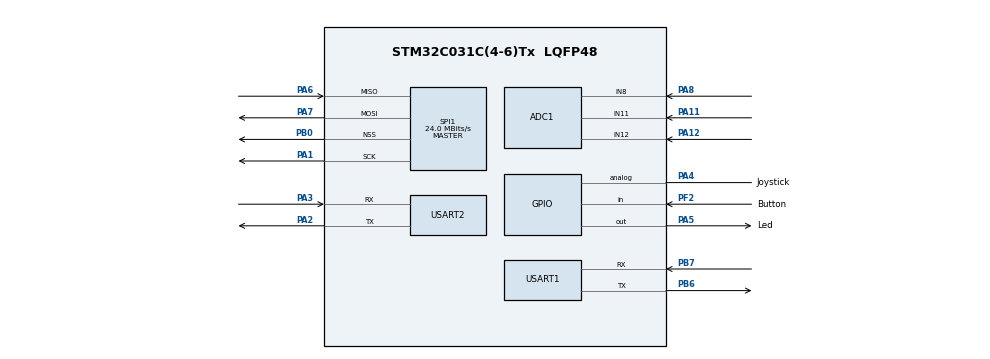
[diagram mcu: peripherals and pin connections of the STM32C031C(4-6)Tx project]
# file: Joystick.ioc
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ADC1.Channel-3\#ChannelRegularConversion=ADC_CHANNEL_11
ADC1.NbrOfConversionFlag=1
ADC1.Rank-3\#ChannelRegularConversion=1
ADC1.SamplingTime-3\#ChannelRegularConversion=ADC_SAMPLINGTIME_COMMON_1
ADC1.SelectedChannel=ADC_CHANNEL_8|ADC_CHANNEL_11|ADC_CHANNEL_12
ADC1.master=1
Mcu.Family=STM32C0
Mcu.Name=STM32C031C(4-6)Tx
Mcu.Package=LQFP48
NVIC.USART2_IRQn=true\:0\:0\:false\:false\:true\:true\:true\:true
PA1.Mode=Full_Duplex_Master
PA1.Signal=SPI1_SCK
PA11\ [PA9].Mode=IN11
PA11\ [PA9].Signal=ADC1_IN11
PA12\ [PA10].Mode=IN12
PA12\ [PA10].Signal=ADC1_IN12
PA13.Mode=Serial_Wire
PA13.Signal=DEBUG_SWDIO
PA14-BOOT0.Mode=Serial_Wire
PA14-BOOT0.Signal=DEBUG_SWCLK
PA2.Mode=Asynchronous
PA2.Signal=USART2_TX
PA3.Mode=Asynchronous
PA3.Signal=USART2_RX
PA4.GPIO_Label=Joystick
PA4.GPIO_Mode=GPIO_MODE_ANALOG
PA4.Signal=GPIO_Analog
PA5.GPIO_Label=Led
PA5.GPIO_ModeDefaultOutputPP=GPIO_MODE_OUTPUT_PP
PA5.GPIO_PuPd=GPIO_NOPULL
PA5.GPIO_Speed=GPIO_SPEED_FREQ_VERY_HIGH
PA5.PinState=GPIO_PIN_SET
PA5.Signal=GPIO_Output
PA6.Mode=Full_Duplex_Master
PA6.Signal=SPI1_MISO
PA7.Mode=Full_Duplex_Master
PA7.Signal=SPI1_MOSI
PA8.Mode=IN8
PA8.Signal=ADC1_IN8
PB0.Mode=NSS_Signal_Hard_Output
PB0.Signal=SPI1_NSS
PB6.Mode=Asynchronous
PB6.Signal=USART1_TX
PB7.Mode=Asynchronous
PB7.Signal=USART1_RX
PC14-OSCX_IN\ (PC14).Mode=LSE-External-Clock-Source
PC14-OSCX_IN\ (PC14).Signal=RCC_OSCX_IN
PF0-OSC_IN\ (PF0).Mode=HSE-External-Oscillator
PF0-OSC_IN\ (PF0).Signal=RCC_OSC_IN
PF1-OSC_OUT\ (PF1).Mode=HSE-External-Oscillator
PF1-OSC_OUT\ (PF1).Signal=RCC_OSC_OUT
PF2-NRST.GPIO_Label=Button
PF2-NRST.Signal=GPIO_Input
ProjectManager.HeapSize=0x200
ProjectManager.StackSize=0x400
ProjectManager.TargetToolchain=STM32CubeIDE
RCC.ADCFreq_Value=48000000
RCC.AHBFreq_Value=48000000
RCC.CortexFreq_Value=48000000
RCC.EXTERNAL_CLOCK_VALUE=12288000
RCC.HCLKFreq_Value=48000000
RCC.HSE_VALUE=8000000
RCC.HSISYSCLKDivider=RCC_HSI_DIV1
RCC.HSI_VALUE=48000000
RCC.LSE_VALUE=32768
RCC.SYSCLKFreq_VALUE=48000000
SPI1.CalculateBaudRate=24.0 MBits/s
SPI1.Direction=SPI_DIRECTION_2LINES
SPI1.Mode=SPI_MODE_MASTER
SPI1.VirtualNSS=VM_NSSHARD
SPI1.VirtualType=VM_MASTER
USART1.VirtualMode-Asynchronous=VM_ASYNC
USART2.VirtualMode-Asynchronous=VM_ASYNC
board=STM32C0316-DK

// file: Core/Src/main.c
/* USER CODE BEGIN Header */
/**
  ******************************************************************************
  * @file           : main.c
  * @brief          : Main program body
  ******************************************************************************
  * @attention
  *
  * Copyright (c) 2025 STMicroelectronics.
  * All rights reserved.
  *
  * This software is licensed under terms that can be found in the LICENSE file
  * in the root directory of this software component.
  * If no LICENSE file comes with this software, it is provided AS-IS.
  *
  ******************************************************************************
  */
/* USER CODE END Header */
#include "main.h"
#include <stdio.h>
#include <string.h>

ADC_HandleTypeDef hadc1;

SPI_HandleTypeDef hspi1;

UART_HandleTypeDef huart1;
UART_HandleTypeDef huart2;

void SystemClock_Config(void);
static void MX_GPIO_Init(void);
static void MX_ADC1_Init(void);
static void MX_SPI1_Init(void);
static void MX_USART1_UART_Init(void);
static void MX_USART2_UART_Init(void);

char msg[64];
int main(void)
{

  /* MCU Configuration--------------------------------------------------------*/

  /* Reset of all peripherals, Initializes the Flash interface and the Systick. */
  HAL_Init();

  /* Configure the system clock */
  SystemClock_Config();

  /* Initialize all configured peripherals */
  MX_GPIO_Init();
  MX_ADC1_Init();
  MX_SPI1_Init();
  MX_USART1_UART_Init();
  MX_USART2_UART_Init();
  /* USER CODE BEGIN 2 */
  //const char *msg = "Hello from STM32!\r\n";
  /* USER CODE END 2 */
  uint8_t last_direction = 0;
  /* Infinite loop */
  while (1)
  {
	  ADC_ChannelConfTypeDef sConfig = {0};
	          sConfig.Channel = ADC_CHANNEL_4; // PA4
	          sConfig.Rank = ADC_REGULAR_RANK_1;
	          sConfig.SamplingTime = ADC_SAMPLETIME_3CYCLES_5;
	          HAL_ADC_ConfigChannel(&hadc1, &sConfig);

	          HAL_ADC_Start(&hadc1);
	          HAL_ADC_PollForConversion(&hadc1, 10);
	          uint32_t val = HAL_ADC_GetValue(&hadc1);
	          HAL_ADC_Stop(&hadc1);

	          // --- DEBUG: šalji vrednost na Putty ---
	           //snprintf(msg, sizeof(msg), "ADC=%lu\r\n", val);
	           //HAL_UART_Transmit(&huart1, (uint8_t*)msg, strlen(msg), 100);

	          uint8_t direction = 0;

	          // Pragovi su primer! Testiraj svoje vrednosti!
	          if      (val < 300)     direction = 5; // CLICK
	          else if (val < 900)     direction = 1; // LEFT
	          else if (val < 1700)    direction = 3; // DOWN
	          else if (val < 2600)    direction = 2; // UP
	          else if (val < 3400)    direction = 4; // RIGHT
	          else                    direction = 0; // CENTER

	          // Šalji poruku samo kad promeniš smer
	          if (direction != last_direction)
	          {
	              switch(direction) {
	                  case 1: snprintf(msg, sizeof(msg), "Joystick LEFT\r\n"); break;
	                  case 2: snprintf(msg, sizeof(msg), "Joystick UP\r\n"); break;
	                  case 3: snprintf(msg, sizeof(msg), "Joystick DOWN\r\n"); break;
	                  case 4: snprintf(msg, sizeof(msg), "Joystick RIGHT\r\n"); break;
	                  case 5: snprintf(msg, sizeof(msg), "Joystick CLICK\r\n");
	                  HAL_GPIO_WritePin(GPIOA, GPIO_PIN_5, GPIO_PIN_SET); break;
	                  default: snprintf(msg, sizeof(msg), "Joystick CENTER\r\n");HAL_GPIO_WritePin(GPIOA, GPIO_PIN_5, GPIO_PIN_RESET); break;
	              }
	              HAL_UART_Transmit(&huart1, (uint8_t*)msg, strlen(msg), 100);
	              last_direction = direction;
	          }

	          HAL_Delay(100);
	      }
  }

void SystemClock_Config(void)
{
  RCC_OscInitTypeDef RCC_OscInitStruct = {0};
  RCC_ClkInitTypeDef RCC_ClkInitStruct = {0};

  /** Initializes the RCC Oscillators according to the specified parameters
  * in the RCC_OscInitTypeDef structure.
  */
  RCC_OscInitStruct.OscillatorType = RCC_OSCILLATORTYPE_HSI;
  RCC_OscInitStruct.HSIState = RCC_HSI_ON;
  RCC_OscInitStruct.HSIDiv = RCC_HSI_DIV1;
  RCC_OscInitStruct.HSICalibrationValue = RCC_HSICALIBRATION_DEFAULT;
  if (HAL_RCC_OscConfig(&RCC_OscInitStruct) != HAL_OK)
  {
    Error_Handler();
  }

  /** Initializes the CPU, AHB and APB buses clocks
  */
  RCC_ClkInitStruct.ClockType = RCC_CLOCKTYPE_HCLK|RCC_CLOCKTYPE_SYSCLK
                              |RCC_CLOCKTYPE_PCLK1;
  RCC_ClkInitStruct.SYSCLKSource = RCC_SYSCLKSOURCE_HSI;
  RCC_ClkInitStruct.SYSCLKDivider = RCC_SYSCLK_DIV1;
  RCC_ClkInitStruct.AHBCLKDivider = RCC_HCLK_DIV1;
  RCC_ClkInitStruct.APB1CLKDivider = RCC_APB1_DIV1;

  if (HAL_RCC_ClockConfig(&RCC_ClkInitStruct, FLASH_LATENCY_1) != HAL_OK)
  {
    Error_Handler();
  }
}

static void MX_ADC1_Init(void)
{

  ADC_ChannelConfTypeDef sConfig = {0};

  /** Configure the global features of the ADC (Clock, Resolution, Data Alignment and number of conversion)
  */
  hadc1.Instance = ADC1;
  hadc1.Init.ClockPrescaler = ADC_CLOCK_SYNC_PCLK_DIV2;
  hadc1.Init.Resolution = ADC_RESOLUTION_12B;
  hadc1.Init.DataAlign = ADC_DATAALIGN_RIGHT;
  hadc1.Init.ScanConvMode = ADC_SCAN_DISABLE;
  hadc1.Init.EOCSelection = ADC_EOC_SINGLE_CONV;
  hadc1.Init.LowPowerAutoWait = DISABLE;
  hadc1.Init.LowPowerAutoPowerOff = DISABLE;
  hadc1.Init.ContinuousConvMode = DISABLE;
  hadc1.Init.NbrOfConversion = 1;
  hadc1.Init.DiscontinuousConvMode = DISABLE;
  hadc1.Init.ExternalTrigConv = ADC_SOFTWARE_START;
  hadc1.Init.ExternalTrigConvEdge = ADC_EXTERNALTRIGCONVEDGE_NONE;
  hadc1.Init.DMAContinuousRequests = DISABLE;
  hadc1.Init.Overrun = ADC_OVR_DATA_PRESERVED;
  hadc1.Init.SamplingTimeCommon1 = ADC_SAMPLETIME_1CYCLE_5;
  hadc1.Init.SamplingTimeCommon2 = ADC_SAMPLETIME_1CYCLE_5;
  hadc1.Init.OversamplingMode = DISABLE;
  hadc1.Init.TriggerFrequencyMode = ADC_TRIGGER_FREQ_HIGH;
  if (HAL_ADC_Init(&hadc1) != HAL_OK)
  {
    Error_Handler();
  }

  /** Configure Regular Channel
  */
  sConfig.Channel = ADC_CHANNEL_11;
  sConfig.Rank = ADC_REGULAR_RANK_1;
  sConfig.SamplingTime = ADC_SAMPLINGTIME_COMMON_1;
  if (HAL_ADC_ConfigChannel(&hadc1, &sConfig) != HAL_OK)
  {
    Error_Handler();
  }

}

static void MX_SPI1_Init(void)
{

  /* SPI1 parameter configuration*/
  hspi1.Instance = SPI1;
  hspi1.Init.Mode = SPI_MODE_MASTER;
  hspi1.Init.Direction = SPI_DIRECTION_2LINES;
  hspi1.Init.DataSize = SPI_DATASIZE_8BIT;
  hspi1.Init.CLKPolarity = SPI_POLARITY_LOW;
  hspi1.Init.CLKPhase = SPI_PHASE_1EDGE;
  hspi1.Init.NSS = SPI_NSS_HARD_OUTPUT;
  hspi1.Init.BaudRatePrescaler = SPI_BAUDRATEPRESCALER_2;
  hspi1.Init.FirstBit = SPI_FIRSTBIT_MSB;
  hspi1.Init.TIMode = SPI_TIMODE_DISABLE;
  hspi1.Init.CRCCalculation = SPI_CRCCALCULATION_DISABLE;
  hspi1.Init.CRCPolynomial = 7;
  hspi1.Init.CRCLength = SPI_CRC_LENGTH_DATASIZE;
  hspi1.Init.NSSPMode = SPI_NSS_PULSE_ENABLE;
  if (HAL_SPI_Init(&hspi1) != HAL_OK)
  {
    Error_Handler();
  }

}

static void MX_USART1_UART_Init(void)
{

  huart1.Instance = USART1;
  huart1.Init.BaudRate = 115200;
  huart1.Init.WordLength = UART_WORDLENGTH_8B;
  huart1.Init.StopBits = UART_STOPBITS_1;
  huart1.Init.Parity = UART_PARITY_NONE;
  huart1.Init.Mode = UART_MODE_TX_RX;
  huart1.Init.HwFlowCtl = UART_HWCONTROL_NONE;
  huart1.Init.OverSampling = UART_OVERSAMPLING_16;
  huart1.Init.OneBitSampling = UART_ONE_BIT_SAMPLE_DISABLE;
  huart1.Init.ClockPrescaler = UART_PRESCALER_DIV1;
  huart1.AdvancedInit.AdvFeatureInit = UART_ADVFEATURE_NO_INIT;
  if (HAL_UART_Init(&huart1) != HAL_OK)
  {
    Error_Handler();
  }
  if (HAL_UARTEx_SetTxFifoThreshold(&huart1, UART_TXFIFO_THRESHOLD_1_8) != HAL_OK)
  {
    Error_Handler();
  }
  if (HAL_UARTEx_SetRxFifoThreshold(&huart1, UART_RXFIFO_THRESHOLD_1_8) != HAL_OK)
  {
    Error_Handler();
  }
  if (HAL_UARTEx_DisableFifoMode(&huart1) != HAL_OK)
  {
    Error_Handler();
  }

}

static void MX_USART2_UART_Init(void)
{

  huart2.Instance = USART2;
  huart2.Init.BaudRate = 115200;
  huart2.Init.WordLength = UART_WORDLENGTH_8B;
  huart2.Init.StopBits = UART_STOPBITS_1;
  huart2.Init.Parity = UART_PARITY_NONE;
  huart2.Init.Mode = UART_MODE_TX_RX;
  huart2.Init.HwFlowCtl = UART_HWCONTROL_NONE;
  huart2.Init.OverSampling = UART_OVERSAMPLING_16;
  huart2.Init.OneBitSampling = UART_ONE_BIT_SAMPLE_DISABLE;
  huart2.Init.ClockPrescaler = UART_PRESCALER_DIV1;
  huart2.AdvancedInit.AdvFeatureInit = UART_ADVFEATURE_NO_INIT;
  if (HAL_UART_Init(&huart2) != HAL_OK)
  {
    Error_Handler();
  }

}

static void MX_GPIO_Init(void)
{
  GPIO_InitTypeDef GPIO_InitStruct = {0};

  /* GPIO Ports Clock Enable */
  __HAL_RCC_GPIOC_CLK_ENABLE();
  __HAL_RCC_GPIOF_CLK_ENABLE();
  __HAL_RCC_GPIOA_CLK_ENABLE();
  __HAL_RCC_GPIOB_CLK_ENABLE();

  /*Configure GPIO pin Output Level */
  HAL_GPIO_WritePin(Led_GPIO_Port, Led_Pin, GPIO_PIN_SET);

  /*Configure GPIO pin : Button_Pin */
  GPIO_InitStruct.Pin = Button_Pin;
  GPIO_InitStruct.Mode = GPIO_MODE_INPUT;
  GPIO_InitStruct.Pull = GPIO_NOPULL;
  HAL_GPIO_Init(Button_GPIO_Port, &GPIO_InitStruct);

  /*Configure GPIO pin : Joystick_Pin */
  GPIO_InitStruct.Pin = Joystick_Pin;
  GPIO_InitStruct.Mode = GPIO_MODE_ANALOG;
  GPIO_InitStruct.Pull = GPIO_NOPULL;
  HAL_GPIO_Init(Joystick_GPIO_Port, &GPIO_InitStruct);

  /*Configure GPIO pin : Led_Pin */
  GPIO_InitStruct.Pin = Led_Pin;
  GPIO_InitStruct.Mode = GPIO_MODE_OUTPUT_PP;
  GPIO_InitStruct.Pull = GPIO_NOPULL;
  GPIO_InitStruct.Speed = GPIO_SPEED_FREQ_VERY_HIGH;
  HAL_GPIO_Init(Led_GPIO_Port, &GPIO_InitStruct);

}

void Error_Handler(void)
{
  __disable_irq();
  while (1)
  {
  }
}
